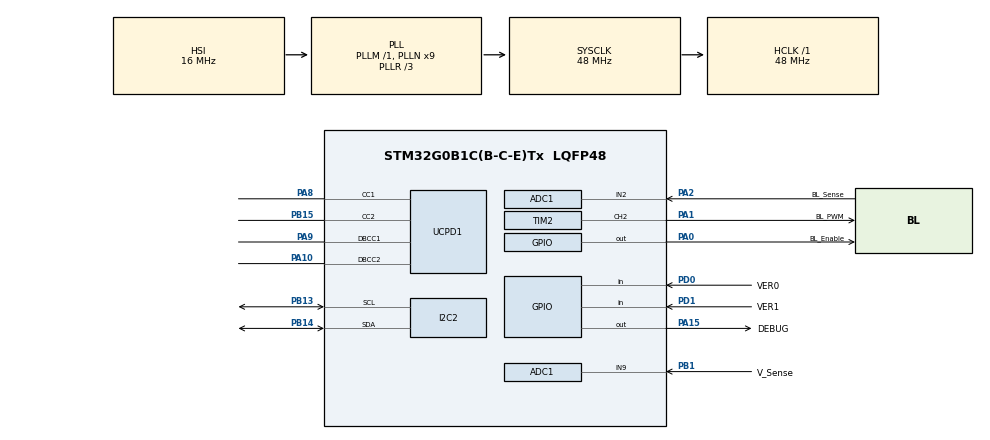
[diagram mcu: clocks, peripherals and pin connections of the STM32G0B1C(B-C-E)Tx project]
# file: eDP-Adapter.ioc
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ADC1.Channel-0\#ChannelRegularConversion=ADC_CHANNEL_9
ADC1.Channel-2\#ChannelRegularConversion=ADC_CHANNEL_2
ADC1.ClockPrescaler=ADC_CLOCK_SYNC_PCLK_DIV2
ADC1.ContinuousConvMode=ENABLE
ADC1.DMAContinuousRequests=ENABLE
ADC1.NbrOfConversion=2
ADC1.NbrOfConversionFlag=1
ADC1.Overrun=ADC_OVR_DATA_OVERWRITTEN
ADC1.Rank-0\#ChannelRegularConversion=1
ADC1.Rank-2\#ChannelRegularConversion=2
ADC1.SamplingTime-0\#ChannelRegularConversion=ADC_SAMPLINGTIME_COMMON_1
ADC1.SamplingTime-2\#ChannelRegularConversion=ADC_SAMPLINGTIME_COMMON_1
ADC1.SamplingTimeCommon1=ADC_SAMPLETIME_160CYCLES_5
ADC1.SamplingTimeCommon2=ADC_SAMPLETIME_160CYCLES_5
ADC1.SelectedChannel=ADC_CHANNEL_2|ADC_CHANNEL_9
ADC1.master=1
Dma.ADC1.2.Direction=DMA_PERIPH_TO_MEMORY
Dma.ADC1.2.EventEnable=DISABLE
Dma.ADC1.2.Instance=DMA1_Channel3
Dma.ADC1.2.MemDataAlignment=DMA_MDATAALIGN_WORD
Dma.ADC1.2.MemInc=DMA_MINC_ENABLE
Dma.ADC1.2.Mode=DMA_CIRCULAR
Dma.ADC1.2.PeriphDataAlignment=DMA_PDATAALIGN_WORD
Dma.ADC1.2.PeriphInc=DMA_PINC_DISABLE
Dma.ADC1.2.Polarity=HAL_DMAMUX_REQ_GEN_RISING
Dma.ADC1.2.Priority=DMA_PRIORITY_LOW
Dma.ADC1.2.RequestNumber=1
Dma.ADC1.2.SignalID=NONE
Dma.ADC1.2.SyncEnable=DISABLE
Dma.ADC1.2.SyncPolarity=HAL_DMAMUX_SYNC_NO_EVENT
Dma.ADC1.2.SyncRequestNumber=1
Dma.ADC1.2.SyncSignalID=NONE
Dma.Request0=UCPD1_RX
Dma.Request1=UCPD1_TX
Dma.Request2=ADC1
Dma.UCPD1_RX.0.Direction=DMA_PERIPH_TO_MEMORY
Dma.UCPD1_RX.0.EventEnable=DISABLE
Dma.UCPD1_RX.0.Instance=DMA1_Channel1
Dma.UCPD1_RX.0.MemDataAlignment=DMA_MDATAALIGN_BYTE
Dma.UCPD1_RX.0.MemInc=DMA_MINC_ENABLE
Dma.UCPD1_RX.0.Mode=DMA_NORMAL
Dma.UCPD1_RX.0.PeriphDataAlignment=DMA_PDATAALIGN_BYTE
Dma.UCPD1_RX.0.PeriphInc=DMA_PINC_DISABLE
Dma.UCPD1_RX.0.Polarity=HAL_DMAMUX_REQ_GEN_RISING
Dma.UCPD1_RX.0.Priority=DMA_PRIORITY_MEDIUM
Dma.UCPD1_RX.0.RequestNumber=1
Dma.UCPD1_RX.0.SignalID=NONE
Dma.UCPD1_RX.0.SyncEnable=DISABLE
Dma.UCPD1_RX.0.SyncPolarity=HAL_DMAMUX_SYNC_NO_EVENT
Dma.UCPD1_RX.0.SyncRequestNumber=1
Dma.UCPD1_RX.0.SyncSignalID=NONE
Dma.UCPD1_TX.1.Direction=DMA_MEMORY_TO_PERIPH
Dma.UCPD1_TX.1.EventEnable=DISABLE
Dma.UCPD1_TX.1.Instance=DMA1_Channel2
Dma.UCPD1_TX.1.MemDataAlignment=DMA_MDATAALIGN_BYTE
Dma.UCPD1_TX.1.MemInc=DMA_MINC_ENABLE
Dma.UCPD1_TX.1.Mode=DMA_NORMAL
Dma.UCPD1_TX.1.PeriphDataAlignment=DMA_PDATAALIGN_BYTE
Dma.UCPD1_TX.1.PeriphInc=DMA_PINC_DISABLE
Dma.UCPD1_TX.1.Polarity=HAL_DMAMUX_REQ_GEN_RISING
Dma.UCPD1_TX.1.Priority=DMA_PRIORITY_MEDIUM
Dma.UCPD1_TX.1.RequestNumber=1
Dma.UCPD1_TX.1.SignalID=NONE
Dma.UCPD1_TX.1.SyncEnable=DISABLE
Dma.UCPD1_TX.1.SyncPolarity=HAL_DMAMUX_SYNC_NO_EVENT
Dma.UCPD1_TX.1.SyncRequestNumber=1
Dma.UCPD1_TX.1.SyncSignalID=NONE
FREERTOS.Tasks01=defaultTask,24,128,StartDefaultTask,Default,NULL,Dynamic,NULL,NULL
FREERTOS.configTOTAL_HEAP_SIZE=16384
I2C2.Timing=0x10805D88
Mcu.Family=STM32G0
Mcu.Name=STM32G0B1C(B-C-E)Tx
Mcu.Package=LQFP48
Mcu.UserConstants=VDDA_APPLI,3300
NVIC.DMA1_Channel1_IRQn=true\:3\:0\:false\:false\:true\:true\:false\:true\:true
NVIC.DMA1_Channel2_3_IRQn=true\:3\:0\:false\:false\:true\:true\:false\:true\:true
NVIC.USB_UCPD1_2_IRQn=true\:3\:0\:false\:false\:true\:true\:true\:true\:true
PA0.GPIO_Label=BL_Enable
PA0.Signal=GPIO_Output
PA1.GPIO_Label=BL_PWM
PA1.Signal=S_TIM2_CH2
PA10.Mode=EnableDeadBattery
PA10.Signal=UCPD1_DBCC2
PA13.Mode=Serial_Wire
PA13.Signal=SYS_SWDIO
PA14-BOOT0.Mode=Serial_Wire
PA14-BOOT0.Signal=SYS_SWCLK
PA15.GPIO_Label=DEBUG
PA15.Signal=GPIO_Output
PA2.GPIO_Label=BL_Sense
PA2.Mode=IN2
PA2.Signal=ADC1_IN2
PA8.Mode=Sink_AllSignals
PA8.Signal=UCPD1_CC1
PA9.Mode=EnableDeadBattery
PA9.Signal=UCPD1_DBCC1
PB1.GPIO_Label=V_Sense
PB1.Mode=IN9
PB1.Signal=ADC1_IN9
PB13.Mode=I2C
PB13.Signal=I2C2_SCL
PB14.Mode=I2C
PB14.Signal=I2C2_SDA
PB15.Mode=Sink_AllSignals
PB15.Signal=UCPD1_CC2
PD0.GPIO_Label=VER0
PD0.GPIO_PuPd=GPIO_PULLUP
PD0.Signal=GPIO_Input
PD1.GPIO_Label=VER1
PD1.GPIO_PuPd=GPIO_PULLUP
PD1.Signal=GPIO_Input
ProjectManager.HeapSize=0x800
ProjectManager.StackSize=0x800
ProjectManager.TargetToolchain=STM32CubeIDE
RCC.ADCFreq_Value=48000000
RCC.AHBFreq_Value=48000000
RCC.CortexFreq_Value=48000000
RCC.EXTERNAL_CLOCK_VALUE=48000
RCC.HCLKFreq_Value=48000000
RCC.HSE_VALUE=8000000
RCC.HSI48_VALUE=48000000
RCC.HSI_VALUE=16000000
RCC.LSE_VALUE=32768
RCC.PLLN=9
RCC.PLLR=RCC_PLLR_DIV3
RCC.SYSCLKFreq_VALUE=48000000
RCC.SYSCLKSource=RCC_SYSCLKSOURCE_PLLCLK
RCC.USBFreq_Value=48000000
RCC.VCOOutputFreq_Value=144000000
SH.S_TIM2_CH2.0=TIM2_CH2,PWM Generation2 CH2
TIM2.AutoReloadPreload=TIM_AUTORELOAD_PRELOAD_ENABLE
TIM2.Channel-PWM\ Generation2\ CH2=TIM_CHANNEL_2
TIM2.CounterMode=TIM_COUNTERMODE_DOWN
TIM2.Period=0x00003FFF
TIM2.Pulse-PWM\ Generation2\ CH2=0
USBPD.PE_DR_Swap_To_DFP_P0=USBPD_FALSE
USBPD.PE_RespondsToDiscovSOP_P0=USBPD_TRUE
USBPD.PE_VDMSupport_P0=USBPD_TRUE
USBPD.USBPD_PORT0_PDO_SNK_FIXED_SET_OP_CURRENT_0=3000
USBPD.USBPD_PORT0_PDO_SNK_FIXED_SET_OP_CURRENT_1=1800
USBPD.USBPD_PORT0_PDO_SNK_FIXED_SET_VOLTAGE_1=9000
USBPD.USBPD_PORT0_PDO_SNK_NB=1
USBPD.VDM_ProductTypeUFPorCP_P0=PRODUCT_TYPE_AMA
VP_FREERTOS_VS_CMSIS_V2.Mode=CMSIS_V2
VP_SYS_VS_DBSignals.Mode=DisableDeadBatterySignals
VP_TIM2_VS_ClockSourceINT.Mode=Internal
VP_USBPD_VS_PD3FULL.Mode=PD3_Full_Stack
VP_USBPD_VS_USBPD1.Mode=USBPD_P0
VP_USBPD_VS_usbpd_tim1.Mode=TIM1
board=custom

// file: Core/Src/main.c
/* USER CODE BEGIN Header */
/**
  ******************************************************************************
  * @file           : main.c
  * @brief          : Main program body
  ******************************************************************************
  * @attention
  *
  * Copyright (c) 2025 STMicroelectronics.
  * All rights reserved.
  *
  * This software is licensed under terms that can be found in the LICENSE file
  * in the root directory of this software component.
  * If no LICENSE file comes with this software, it is provided AS-IS.
  *
  ******************************************************************************
  */
/* USER CODE END Header */
#include "main.h"
#include "cmsis_os.h"
#include "usbpd.h"

/* USER CODE BEGIN Includes */
#include "eDP_adapt.h"

/* USER CODE END Includes */

ADC_HandleTypeDef hadc1;
DMA_HandleTypeDef hdma_adc1;

I2C_HandleTypeDef hi2c2;

TIM_HandleTypeDef htim2;

/* Definitions for defaultTask */
osThreadId_t defaultTaskHandle;
const osThreadAttr_t defaultTask_attributes = {
  .name = "defaultTask",
  .priority = (osPriority_t) osPriorityNormal,
  .stack_size = 128 * 4
};

void SystemClock_Config(void);
static void MX_GPIO_Init(void);
static void MX_DMA_Init(void);
static void MX_ADC1_Init(void);
static void MX_UCPD1_Init(void);
static void MX_TIM2_Init(void);
static void MX_I2C2_Init(void);
void StartDefaultTask(void *argument);

int main(void)
{

  /* MCU Configuration--------------------------------------------------------*/

  /* Reset of all peripherals, Initializes the Flash interface and the Systick. */
  HAL_Init();

  /* Configure the system clock */
  SystemClock_Config();

  /* Initialize all configured peripherals */
  MX_GPIO_Init();
  MX_DMA_Init();
  MX_ADC1_Init();
  MX_UCPD1_Init();
  MX_TIM2_Init();
  MX_I2C2_Init();

  /* Init scheduler */
  osKernelInitialize();
  /* USBPD initialisation ---------------------------------*/
  MX_USBPD_Init();

  /* Create the thread(s) */
  /* creation of defaultTask */
  defaultTaskHandle = osThreadNew(StartDefaultTask, NULL, &defaultTask_attributes);

  /* Start scheduler */
  osKernelStart();

  /* We should never get here as control is now taken by the scheduler */

  /* Infinite loop */
  while (1)
  {

  }
}

void SystemClock_Config(void)
{
  RCC_OscInitTypeDef RCC_OscInitStruct = {0};
  RCC_ClkInitTypeDef RCC_ClkInitStruct = {0};

  /** Configure the main internal regulator output voltage
  */
  HAL_PWREx_ControlVoltageScaling(PWR_REGULATOR_VOLTAGE_SCALE1);

  /** Initializes the RCC Oscillators according to the specified parameters
  * in the RCC_OscInitTypeDef structure.
  */
  RCC_OscInitStruct.OscillatorType = RCC_OSCILLATORTYPE_HSI;
  RCC_OscInitStruct.HSIState = RCC_HSI_ON;
  RCC_OscInitStruct.HSIDiv = RCC_HSI_DIV1;
  RCC_OscInitStruct.HSICalibrationValue = RCC_HSICALIBRATION_DEFAULT;
  RCC_OscInitStruct.PLL.PLLState = RCC_PLL_ON;
  RCC_OscInitStruct.PLL.PLLSource = RCC_PLLSOURCE_HSI;
  RCC_OscInitStruct.PLL.PLLM = RCC_PLLM_DIV1;
  RCC_OscInitStruct.PLL.PLLN = 9;
  RCC_OscInitStruct.PLL.PLLP = RCC_PLLP_DIV2;
  RCC_OscInitStruct.PLL.PLLQ = RCC_PLLQ_DIV2;
  RCC_OscInitStruct.PLL.PLLR = RCC_PLLR_DIV3;
  if (HAL_RCC_OscConfig(&RCC_OscInitStruct) != HAL_OK)
  {
    Error_Handler();
  }

  /** Initializes the CPU, AHB and APB buses clocks
  */
  RCC_ClkInitStruct.ClockType = RCC_CLOCKTYPE_HCLK|RCC_CLOCKTYPE_SYSCLK
                              |RCC_CLOCKTYPE_PCLK1;
  RCC_ClkInitStruct.SYSCLKSource = RCC_SYSCLKSOURCE_PLLCLK;
  RCC_ClkInitStruct.AHBCLKDivider = RCC_SYSCLK_DIV1;
  RCC_ClkInitStruct.APB1CLKDivider = RCC_HCLK_DIV1;

  if (HAL_RCC_ClockConfig(&RCC_ClkInitStruct, FLASH_LATENCY_1) != HAL_OK)
  {
    Error_Handler();
  }
}

static void MX_ADC1_Init(void)
{

  ADC_ChannelConfTypeDef sConfig = {0};

  /** Configure the global features of the ADC (Clock, Resolution, Data Alignment and number of conversion)
  */
  hadc1.Instance = ADC1;
  hadc1.Init.ClockPrescaler = ADC_CLOCK_SYNC_PCLK_DIV2;
  hadc1.Init.Resolution = ADC_RESOLUTION_12B;
  hadc1.Init.DataAlign = ADC_DATAALIGN_RIGHT;
  hadc1.Init.ScanConvMode = ADC_SCAN_ENABLE;
  hadc1.Init.EOCSelection = ADC_EOC_SINGLE_CONV;
  hadc1.Init.LowPowerAutoWait = DISABLE;
  hadc1.Init.LowPowerAutoPowerOff = DISABLE;
  hadc1.Init.ContinuousConvMode = ENABLE;
  hadc1.Init.NbrOfConversion = 2;
  hadc1.Init.ExternalTrigConv = ADC_SOFTWARE_START;
  hadc1.Init.ExternalTrigConvEdge = ADC_EXTERNALTRIGCONVEDGE_NONE;
  hadc1.Init.DMAContinuousRequests = ENABLE;
  hadc1.Init.Overrun = ADC_OVR_DATA_OVERWRITTEN;
  hadc1.Init.SamplingTimeCommon1 = ADC_SAMPLETIME_160CYCLES_5;
  hadc1.Init.SamplingTimeCommon2 = ADC_SAMPLETIME_160CYCLES_5;
  hadc1.Init.OversamplingMode = DISABLE;
  hadc1.Init.TriggerFrequencyMode = ADC_TRIGGER_FREQ_HIGH;
  if (HAL_ADC_Init(&hadc1) != HAL_OK)
  {
    Error_Handler();
  }

  /** Configure Regular Channel
  */
  sConfig.Channel = ADC_CHANNEL_9;
  sConfig.Rank = ADC_REGULAR_RANK_1;
  sConfig.SamplingTime = ADC_SAMPLINGTIME_COMMON_1;
  if (HAL_ADC_ConfigChannel(&hadc1, &sConfig) != HAL_OK)
  {
    Error_Handler();
  }

  /** Configure Regular Channel
  */
  sConfig.Channel = ADC_CHANNEL_2;
  sConfig.Rank = ADC_REGULAR_RANK_2;
  if (HAL_ADC_ConfigChannel(&hadc1, &sConfig) != HAL_OK)
  {
    Error_Handler();
  }
  /* USER CODE BEGIN ADC1_Init 2 */
  HAL_ADCEx_Calibration_Start(&hadc1);
  HAL_ADC_Start_DMA(&hadc1, ADC_Vals, 2);
  /* USER CODE END ADC1_Init 2 */

}

static void MX_I2C2_Init(void)
{

  hi2c2.Instance = I2C2;
  hi2c2.Init.Timing = 0x10805D88;
  hi2c2.Init.OwnAddress1 = 0;
  hi2c2.Init.AddressingMode = I2C_ADDRESSINGMODE_7BIT;
  hi2c2.Init.DualAddressMode = I2C_DUALADDRESS_DISABLE;
  hi2c2.Init.OwnAddress2 = 0;
  hi2c2.Init.OwnAddress2Masks = I2C_OA2_NOMASK;
  hi2c2.Init.GeneralCallMode = I2C_GENERALCALL_DISABLE;
  hi2c2.Init.NoStretchMode = I2C_NOSTRETCH_DISABLE;
  if (HAL_I2C_Init(&hi2c2) != HAL_OK)
  {
    Error_Handler();
  }

  /** Configure Analogue filter
  */
  if (HAL_I2CEx_ConfigAnalogFilter(&hi2c2, I2C_ANALOGFILTER_ENABLE) != HAL_OK)
  {
    Error_Handler();
  }

  /** Configure Digital filter
  */
  if (HAL_I2CEx_ConfigDigitalFilter(&hi2c2, 0) != HAL_OK)
  {
    Error_Handler();
  }

}

static void MX_TIM2_Init(void)
{

  TIM_ClockConfigTypeDef sClockSourceConfig = {0};
  TIM_MasterConfigTypeDef sMasterConfig = {0};
  TIM_OC_InitTypeDef sConfigOC = {0};

  htim2.Instance = TIM2;
  htim2.Init.Prescaler = 0;
  htim2.Init.CounterMode = TIM_COUNTERMODE_DOWN;
  htim2.Init.Period = 0x00003FFF;
  htim2.Init.ClockDivision = TIM_CLOCKDIVISION_DIV1;
  htim2.Init.AutoReloadPreload = TIM_AUTORELOAD_PRELOAD_ENABLE;
  if (HAL_TIM_Base_Init(&htim2) != HAL_OK)
  {
    Error_Handler();
  }
  sClockSourceConfig.ClockSource = TIM_CLOCKSOURCE_INTERNAL;
  if (HAL_TIM_ConfigClockSource(&htim2, &sClockSourceConfig) != HAL_OK)
  {
    Error_Handler();
  }
  if (HAL_TIM_PWM_Init(&htim2) != HAL_OK)
  {
    Error_Handler();
  }
  sMasterConfig.MasterOutputTrigger = TIM_TRGO_RESET;
  sMasterConfig.MasterSlaveMode = TIM_MASTERSLAVEMODE_DISABLE;
  if (HAL_TIMEx_MasterConfigSynchronization(&htim2, &sMasterConfig) != HAL_OK)
  {
    Error_Handler();
  }
  sConfigOC.OCMode = TIM_OCMODE_PWM1;
  sConfigOC.Pulse = 0;
  sConfigOC.OCPolarity = TIM_OCPOLARITY_HIGH;
  sConfigOC.OCFastMode = TIM_OCFAST_DISABLE;
  if (HAL_TIM_PWM_ConfigChannel(&htim2, &sConfigOC, TIM_CHANNEL_2) != HAL_OK)
  {
    Error_Handler();
  }
  HAL_TIM_MspPostInit(&htim2);

}

static void MX_UCPD1_Init(void)
{

  LL_GPIO_InitTypeDef GPIO_InitStruct = {0};

  /* Peripheral clock enable */
  LL_APB1_GRP1_EnableClock(LL_APB1_GRP1_PERIPH_UCPD1);

  LL_IOP_GRP1_EnableClock(LL_IOP_GRP1_PERIPH_GPIOB);
  LL_IOP_GRP1_EnableClock(LL_IOP_GRP1_PERIPH_GPIOA);
  /**UCPD1 GPIO Configuration
  PB15   ------> UCPD1_CC2
  PA8   ------> UCPD1_CC1
  */
  GPIO_InitStruct.Pin = LL_GPIO_PIN_15;
  GPIO_InitStruct.Mode = LL_GPIO_MODE_ANALOG;
  GPIO_InitStruct.Pull = LL_GPIO_PULL_NO;
  LL_GPIO_Init(GPIOB, &GPIO_InitStruct);

  GPIO_InitStruct.Pin = LL_GPIO_PIN_8;
  GPIO_InitStruct.Mode = LL_GPIO_MODE_ANALOG;
  GPIO_InitStruct.Pull = LL_GPIO_PULL_NO;
  LL_GPIO_Init(GPIOA, &GPIO_InitStruct);

  /* UCPD1 DMA Init */

  /* UCPD1_RX Init */
  LL_DMA_SetPeriphRequest(DMA1, LL_DMA_CHANNEL_1, LL_DMAMUX_REQ_UCPD1_RX);

  LL_DMA_SetDataTransferDirection(DMA1, LL_DMA_CHANNEL_1, LL_DMA_DIRECTION_PERIPH_TO_MEMORY);

  LL_DMA_SetChannelPriorityLevel(DMA1, LL_DMA_CHANNEL_1, LL_DMA_PRIORITY_MEDIUM);

  LL_DMA_SetMode(DMA1, LL_DMA_CHANNEL_1, LL_DMA_MODE_NORMAL);

  LL_DMA_SetPeriphIncMode(DMA1, LL_DMA_CHANNEL_1, LL_DMA_PERIPH_NOINCREMENT);

  LL_DMA_SetMemoryIncMode(DMA1, LL_DMA_CHANNEL_1, LL_DMA_MEMORY_INCREMENT);

  LL_DMA_SetPeriphSize(DMA1, LL_DMA_CHANNEL_1, LL_DMA_PDATAALIGN_BYTE);

  LL_DMA_SetMemorySize(DMA1, LL_DMA_CHANNEL_1, LL_DMA_MDATAALIGN_BYTE);

  /* UCPD1_TX Init */
  LL_DMA_SetPeriphRequest(DMA1, LL_DMA_CHANNEL_2, LL_DMAMUX_REQ_UCPD1_TX);

  LL_DMA_SetDataTransferDirection(DMA1, LL_DMA_CHANNEL_2, LL_DMA_DIRECTION_MEMORY_TO_PERIPH);

  LL_DMA_SetChannelPriorityLevel(DMA1, LL_DMA_CHANNEL_2, LL_DMA_PRIORITY_MEDIUM);

  LL_DMA_SetMode(DMA1, LL_DMA_CHANNEL_2, LL_DMA_MODE_NORMAL);

  LL_DMA_SetPeriphIncMode(DMA1, LL_DMA_CHANNEL_2, LL_DMA_PERIPH_NOINCREMENT);

  LL_DMA_SetMemoryIncMode(DMA1, LL_DMA_CHANNEL_2, LL_DMA_MEMORY_INCREMENT);

  LL_DMA_SetPeriphSize(DMA1, LL_DMA_CHANNEL_2, LL_DMA_PDATAALIGN_BYTE);

  LL_DMA_SetMemorySize(DMA1, LL_DMA_CHANNEL_2, LL_DMA_MDATAALIGN_BYTE);

  /* UCPD1 interrupt Init */
  NVIC_SetPriority(USB_UCPD1_2_IRQn, 3);
  NVIC_EnableIRQ(USB_UCPD1_2_IRQn);

}

static void MX_DMA_Init(void)
{

  /* DMA controller clock enable */
  __HAL_RCC_DMA1_CLK_ENABLE();

  /* DMA interrupt init */
  /* DMA1_Channel1_IRQn interrupt configuration */
  NVIC_SetPriority(DMA1_Channel1_IRQn, 3);
  NVIC_EnableIRQ(DMA1_Channel1_IRQn);
  /* DMA1_Channel2_3_IRQn interrupt configuration */
  HAL_NVIC_SetPriority(DMA1_Channel2_3_IRQn, 3, 0);
  HAL_NVIC_EnableIRQ(DMA1_Channel2_3_IRQn);

}

static void MX_GPIO_Init(void)
{
  GPIO_InitTypeDef GPIO_InitStruct = {0};

  /* GPIO Ports Clock Enable */
  __HAL_RCC_GPIOA_CLK_ENABLE();
  __HAL_RCC_GPIOB_CLK_ENABLE();
  __HAL_RCC_GPIOD_CLK_ENABLE();

  /*Configure GPIO pin Output Level */
  HAL_GPIO_WritePin(GPIOA, BL_Enable_Pin|DEBUG_Pin, GPIO_PIN_RESET);

  /*Configure GPIO pins : BL_Enable_Pin DEBUG_Pin */
  GPIO_InitStruct.Pin = BL_Enable_Pin|DEBUG_Pin;
  GPIO_InitStruct.Mode = GPIO_MODE_OUTPUT_PP;
  GPIO_InitStruct.Pull = GPIO_NOPULL;
  GPIO_InitStruct.Speed = GPIO_SPEED_FREQ_LOW;
  HAL_GPIO_Init(GPIOA, &GPIO_InitStruct);

  /*Configure GPIO pins : VER0_Pin VER1_Pin */
  GPIO_InitStruct.Pin = VER0_Pin|VER1_Pin;
  GPIO_InitStruct.Mode = GPIO_MODE_INPUT;
  GPIO_InitStruct.Pull = GPIO_PULLUP;
  HAL_GPIO_Init(GPIOD, &GPIO_InitStruct);

}

void StartDefaultTask(void *argument)
{
  /* USER CODE BEGIN 5 */
	initTask();
  /* Infinite loop */

  for(;;)
  {
	mainLoop();
  }
  /* USER CODE END 5 */
}

void Error_Handler(void)
{
  __disable_irq();
  while (1)
  {
  }
}
